AUTOSAR XML (schema 4-2-2)
package /ASWC_ASW_COM_STD
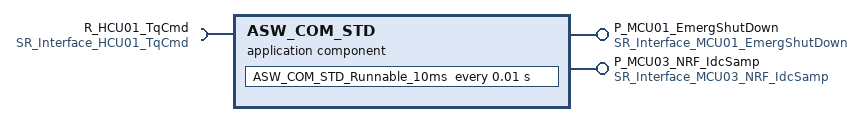
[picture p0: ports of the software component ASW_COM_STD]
  application sw component type ASW_COM_STD
    provide port P_MCU01_EmergShutDown: provided-interface=SR_Interface_MCU01_EmergShutDown
    provide port P_MCU03_NRF_IdcSamp: provided-interface=SR_Interface_MCU03_NRF_IdcSamp
    require port R_HCU01_TqCmd: nonqueued-receiver-com-spec{data-element=HCU01_TqCmd, alive-timeout=0.3}, required-interface=SR_Interface_HCU01_TqCmd
    behavior IB_ASW_COM_STD
      timing event TE_ASW_COM_STD_Runnable_10ms: start-on-event=ASW_COM_STD_Runnable_10ms, period=0.01
      runnable ASW_COM_STD_Runnable_10ms
        data-read-access:
          access READ_R_HCU01_TqCmd_HCU01_TqCmd: accessed-variable=R_HCU01_TqCmd.HCU01_TqCmd
        data-write-access:
          access WRITE_P_MCU01_EmergShutDown_MCU01_EmergShutDown: accessed-variable=P_MCU01_EmergShutDown.MCU01_EmergShutDown
          access WRITE_P_MCU03_NRF_IdcSamp_MCU03_NRF_IdcSamp: accessed-variable=P_MCU03_NRF_IdcSamp.MCU03_NRF_IdcSamp
